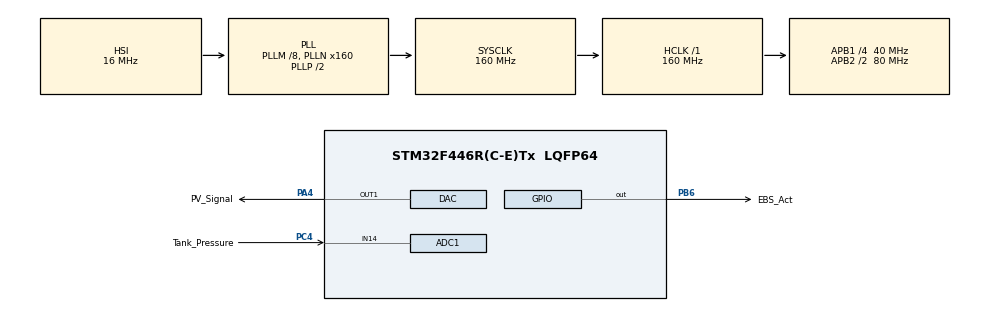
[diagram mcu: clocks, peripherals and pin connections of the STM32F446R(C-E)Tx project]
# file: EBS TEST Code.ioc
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ADC1.Channel-0\#ChannelRegularConversion=ADC_CHANNEL_14
ADC1.ContinuousConvMode=ENABLE
ADC1.DMAContinuousRequests=ENABLE
ADC1.NbrOfConversion=1
ADC1.NbrOfConversionFlag=1
ADC1.Rank-0\#ChannelRegularConversion=1
ADC1.SamplingTime-0\#ChannelRegularConversion=ADC_SAMPLETIME_84CYCLES
ADC1.master=1
DAC.DAC_OutputBuffer=DAC_OUTPUTBUFFER_ENABLE
Dma.ADC1.0.Direction=DMA_PERIPH_TO_MEMORY
Dma.ADC1.0.FIFOMode=DMA_FIFOMODE_DISABLE
Dma.ADC1.0.Instance=DMA2_Stream0
Dma.ADC1.0.MemDataAlignment=DMA_MDATAALIGN_HALFWORD
Dma.ADC1.0.MemInc=DMA_MINC_ENABLE
Dma.ADC1.0.Mode=DMA_CIRCULAR
Dma.ADC1.0.PeriphDataAlignment=DMA_PDATAALIGN_HALFWORD
Dma.ADC1.0.PeriphInc=DMA_PINC_DISABLE
Dma.ADC1.0.Priority=DMA_PRIORITY_LOW
Dma.Request0=ADC1
Mcu.Family=STM32F4
Mcu.Name=STM32F446R(C-E)Tx
Mcu.Package=LQFP64
NVIC.DMA2_Stream0_IRQn=true\:0\:0\:false\:false\:true\:false\:true\:true
NVIC.PriorityGroup=NVIC_PRIORITYGROUP_4
NVIC.TIM6_DAC_IRQn=true\:0\:0\:false\:false\:true\:true\:true\:true
PA13.Mode=Trace_Asynchronous_SW
PA13.Signal=SYS_JTMS-SWDIO
PA14.Mode=Trace_Asynchronous_SW
PA14.Signal=SYS_JTCK-SWCLK
PA4.GPIO_Label=PV_Signal
PA4.Signal=COMP_DAC1_group
PB3.Mode=Trace_Asynchronous_SW
PB3.Signal=SYS_JTDO-SWO
PB6.GPIO_Label=EBS_Act
PB6.Signal=GPIO_Output
PC4.GPIO_Label=Tank_Pressure
PC4.Signal=ADCx_IN14
PH0-OSC_IN.Mode=HSE-External-Oscillator
PH0-OSC_IN.Signal=RCC_OSC_IN
PH1-OSC_OUT.Mode=HSE-External-Oscillator
PH1-OSC_OUT.Signal=RCC_OSC_OUT
ProjectManager.HeapSize=0x200
ProjectManager.StackSize=0x400
ProjectManager.TargetToolchain=STM32CubeIDE
RCC.AHBFreq_Value=160000000
RCC.APB1CLKDivider=RCC_HCLK_DIV4
RCC.APB1Freq_Value=40000000
RCC.APB1TimFreq_Value=80000000
RCC.APB2CLKDivider=RCC_HCLK_DIV2
RCC.APB2Freq_Value=80000000
RCC.APB2TimFreq_Value=160000000
RCC.CortexFreq_Value=160000000
RCC.HCLKFreq_Value=160000000
RCC.PLLM=8
RCC.PLLN=160
RCC.SYSCLKFreq_VALUE=160000000
RCC.SYSCLKSource=RCC_SYSCLKSOURCE_PLLCLK
RCC.USBFreq_Value=160000000
RCC.VCOOutputFreq_Value=320000000
SH.ADCx_IN14.0=ADC1_IN14,IN14
SH.COMP_DAC1_group.0=DAC_OUT1,DAC_OUT1
TIM6.Period=99
TIM6.Prescaler=7999
VP_TIM6_VS_ClockSourceINT.Mode=Enable_Timer
board=custom

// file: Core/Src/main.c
/* USER CODE BEGIN Header */
/**
  ******************************************************************************
  * @file           : main.c
  * @brief          : Main program body
  ******************************************************************************
  * @attention
  *
  * Copyright (c) 2026 STMicroelectronics.
  * All rights reserved.
  *
  * This software is licensed under terms that can be found in the LICENSE file
  * in the root directory of this software component.
  * If no LICENSE file comes with this software, it is provided AS-IS.
  *
  ******************************************************************************
  */
/* USER CODE END Header */
#include "main.h"

/* USER CODE BEGIN Includes */
#include <stdbool.h>
/* USER CODE END Includes */

ADC_HandleTypeDef hadc1;
DMA_HandleTypeDef hdma_adc1;

DAC_HandleTypeDef hdac;

TIM_HandleTypeDef htim6;

/* USER CODE BEGIN PV */
volatile uint16_t adc_raw = 0, value,adc_mV = 0;
volatile uint32_t samples=0;
volatile uint8_t a=1, NO_Valve=0, prev_case=0xFF ;
volatile bool pv_pin_gpio_low=false;
/* USER CODE END PV */

void SystemClock_Config(void);
static void MX_GPIO_Init(void);
static void MX_DMA_Init(void);
static void MX_ADC1_Init(void);
static void MX_TIM6_Init(void);
static void MX_DAC_Init(void);
/* USER CODE BEGIN PFP */
static void reset_all(void);
static void PV_Force_GpioLow(void);
static void PV_Output_Update(uint16_t cmd);
/* USER CODE END PFP */

int main(void)
{

  /* MCU Configuration--------------------------------------------------------*/

  /* Reset of all peripherals, Initializes the Flash interface and the Systick. */
  HAL_Init();

  /* Configure the system clock */
  SystemClock_Config();

  /* Initialize all configured peripherals */
  MX_GPIO_Init();
  MX_DMA_Init();
  MX_ADC1_Init();
  MX_TIM6_Init();
  MX_DAC_Init();
  /* USER CODE BEGIN 2 */
  if (HAL_DAC_Start(&hdac, DAC_CHANNEL_1) != HAL_OK) {
	  Error_Handler();
  }

  if (HAL_ADC_Start_DMA(&hadc1, (uint32_t*)&adc_raw, 1) != HAL_OK) {
	  Error_Handler();
  }

  if (HAL_TIM_Base_Start_IT(&htim6) != HAL_OK) {
	  Error_Handler();
  }
  /* USER CODE END 2 */

  /* Infinite loop */
  /* USER CODE BEGIN WHILE */
  while (1){
	  if(a!=prev_case){
		  reset_all();
		  prev_case=a;
		  }

    switch(a){
      case 1: // you are able to set the value to see how can work the proportional valve and even to tune an find the right thresholds
    	  PV_Output_Update(value);
    	  break;
      case 2: // you should see the proportional valve fully energized and the NO valve de-energize
    	  HAL_GPIO_WritePin(EBS_Act_GPIO_Port, EBS_Act_Pin, GPIO_PIN_RESET);
    	  NO_Valve=1; // 0:energize 1:de-energize
          break;
      case 3: // this make PoC that even if have Proportional Valve set in whatever stage, as long as NO pressure override we are going to see this pressure
    	  HAL_GPIO_WritePin(EBS_Act_GPIO_Port, EBS_Act_Pin, GPIO_PIN_RESET);
    	  NO_Valve=1; // 0:energize 1:de-energize
    	  PV_Output_Update(value);
    	  break;
      default:
    	  break;
    }
    /* USER CODE END WHILE */

  }
}

void SystemClock_Config(void)
{
  RCC_OscInitTypeDef RCC_OscInitStruct = {0};
  RCC_ClkInitTypeDef RCC_ClkInitStruct = {0};

  /** Configure the main internal regulator output voltage
  */
  __HAL_RCC_PWR_CLK_ENABLE();
  __HAL_PWR_VOLTAGESCALING_CONFIG(PWR_REGULATOR_VOLTAGE_SCALE1);

  /** Initializes the RCC Oscillators according to the specified parameters
  * in the RCC_OscInitTypeDef structure.
  */
  RCC_OscInitStruct.OscillatorType = RCC_OSCILLATORTYPE_HSI;
  RCC_OscInitStruct.HSIState = RCC_HSI_ON;
  RCC_OscInitStruct.HSICalibrationValue = RCC_HSICALIBRATION_DEFAULT;
  RCC_OscInitStruct.PLL.PLLState = RCC_PLL_ON;
  RCC_OscInitStruct.PLL.PLLSource = RCC_PLLSOURCE_HSI;
  RCC_OscInitStruct.PLL.PLLM = 8;
  RCC_OscInitStruct.PLL.PLLN = 160;
  RCC_OscInitStruct.PLL.PLLP = RCC_PLLP_DIV2;
  RCC_OscInitStruct.PLL.PLLQ = 2;
  RCC_OscInitStruct.PLL.PLLR = 2;
  if (HAL_RCC_OscConfig(&RCC_OscInitStruct) != HAL_OK)
  {
    Error_Handler();
  }

  /** Initializes the CPU, AHB and APB buses clocks
  */
  RCC_ClkInitStruct.ClockType = RCC_CLOCKTYPE_HCLK|RCC_CLOCKTYPE_SYSCLK
                              |RCC_CLOCKTYPE_PCLK1|RCC_CLOCKTYPE_PCLK2;
  RCC_ClkInitStruct.SYSCLKSource = RCC_SYSCLKSOURCE_PLLCLK;
  RCC_ClkInitStruct.AHBCLKDivider = RCC_SYSCLK_DIV1;
  RCC_ClkInitStruct.APB1CLKDivider = RCC_HCLK_DIV4;
  RCC_ClkInitStruct.APB2CLKDivider = RCC_HCLK_DIV2;

  if (HAL_RCC_ClockConfig(&RCC_ClkInitStruct, FLASH_LATENCY_5) != HAL_OK)
  {
    Error_Handler();
  }
}

static void MX_ADC1_Init(void)
{

  ADC_ChannelConfTypeDef sConfig = {0};

  /** Configure the global features of the ADC (Clock, Resolution, Data Alignment and number of conversion)
  */
  hadc1.Instance = ADC1;
  hadc1.Init.ClockPrescaler = ADC_CLOCK_SYNC_PCLK_DIV4;
  hadc1.Init.Resolution = ADC_RESOLUTION_12B;
  hadc1.Init.ScanConvMode = DISABLE;
  hadc1.Init.ContinuousConvMode = ENABLE;
  hadc1.Init.DiscontinuousConvMode = DISABLE;
  hadc1.Init.ExternalTrigConvEdge = ADC_EXTERNALTRIGCONVEDGE_NONE;
  hadc1.Init.ExternalTrigConv = ADC_SOFTWARE_START;
  hadc1.Init.DataAlign = ADC_DATAALIGN_RIGHT;
  hadc1.Init.NbrOfConversion = 1;
  hadc1.Init.DMAContinuousRequests = ENABLE;
  hadc1.Init.EOCSelection = ADC_EOC_SINGLE_CONV;
  if (HAL_ADC_Init(&hadc1) != HAL_OK)
  {
    Error_Handler();
  }

  /** Configure for the selected ADC regular channel its corresponding rank in the sequencer and its sample time.
  */
  sConfig.Channel = ADC_CHANNEL_14;
  sConfig.Rank = 1;
  sConfig.SamplingTime = ADC_SAMPLETIME_84CYCLES;
  if (HAL_ADC_ConfigChannel(&hadc1, &sConfig) != HAL_OK)
  {
    Error_Handler();
  }

}

static void MX_DAC_Init(void)
{

  DAC_ChannelConfTypeDef sConfig = {0};

  /** DAC Initialization
  */
  hdac.Instance = DAC;
  if (HAL_DAC_Init(&hdac) != HAL_OK)
  {
    Error_Handler();
  }

  /** DAC channel OUT1 config
  */
  sConfig.DAC_Trigger = DAC_TRIGGER_NONE;
  sConfig.DAC_OutputBuffer = DAC_OUTPUTBUFFER_ENABLE;
  if (HAL_DAC_ConfigChannel(&hdac, &sConfig, DAC_CHANNEL_1) != HAL_OK)
  {
    Error_Handler();
  }

}

static void MX_TIM6_Init(void)
{

  TIM_MasterConfigTypeDef sMasterConfig = {0};

  htim6.Instance = TIM6;
  htim6.Init.Prescaler = 7999;
  htim6.Init.CounterMode = TIM_COUNTERMODE_UP;
  htim6.Init.Period = 99;
  htim6.Init.AutoReloadPreload = TIM_AUTORELOAD_PRELOAD_DISABLE;
  if (HAL_TIM_Base_Init(&htim6) != HAL_OK)
  {
    Error_Handler();
  }
  sMasterConfig.MasterOutputTrigger = TIM_TRGO_RESET;
  sMasterConfig.MasterSlaveMode = TIM_MASTERSLAVEMODE_DISABLE;
  if (HAL_TIMEx_MasterConfigSynchronization(&htim6, &sMasterConfig) != HAL_OK)
  {
    Error_Handler();
  }

}

static void MX_DMA_Init(void)
{

  /* DMA controller clock enable */
  __HAL_RCC_DMA2_CLK_ENABLE();

  /* DMA interrupt init */
  /* DMA2_Stream0_IRQn interrupt configuration */
  HAL_NVIC_SetPriority(DMA2_Stream0_IRQn, 0, 0);
  HAL_NVIC_EnableIRQ(DMA2_Stream0_IRQn);

}

static void MX_GPIO_Init(void)
{
  GPIO_InitTypeDef GPIO_InitStruct = {0};

  /* GPIO Ports Clock Enable */
  __HAL_RCC_GPIOH_CLK_ENABLE();
  __HAL_RCC_GPIOA_CLK_ENABLE();
  __HAL_RCC_GPIOC_CLK_ENABLE();
  __HAL_RCC_GPIOB_CLK_ENABLE();

  /*Configure GPIO pin Output Level */
  HAL_GPIO_WritePin(EBS_Act_GPIO_Port, EBS_Act_Pin, GPIO_PIN_RESET);

  /*Configure GPIO pin : EBS_Act_Pin */
  GPIO_InitStruct.Pin = EBS_Act_Pin;
  GPIO_InitStruct.Mode = GPIO_MODE_OUTPUT_PP;
  GPIO_InitStruct.Pull = GPIO_NOPULL;
  GPIO_InitStruct.Speed = GPIO_SPEED_FREQ_LOW;
  HAL_GPIO_Init(EBS_Act_GPIO_Port, &GPIO_InitStruct);

}

/* USER CODE BEGIN 4 */
static void reset_all(void){
	NO_Valve=0;
	value=0; // set value variable for pv to 0
	samples=0; // set tim6 samples to zero
	PV_Force_GpioLow(); // set pv_signal pin to gpio_low
	HAL_GPIO_WritePin(EBS_Act_GPIO_Port, EBS_Act_Pin, GPIO_PIN_SET); //energize valve
}

static void PV_Force_GpioLow(void){
	GPIO_InitTypeDef GPIO_InitStruct = {0};

	if (!pv_pin_gpio_low){
		HAL_DAC_Stop(&hdac, DAC_CHANNEL_1);
		GPIO_InitStruct.Pin = PV_Signal_Pin;
		GPIO_InitStruct.Mode = GPIO_MODE_OUTPUT_PP;
		GPIO_InitStruct.Pull = GPIO_NOPULL;
		GPIO_InitStruct.Speed = GPIO_SPEED_FREQ_LOW;
		HAL_GPIO_Init(PV_Signal_GPIO_Port, &GPIO_InitStruct);
		pv_pin_gpio_low = true;
	}

	HAL_GPIO_WritePin(PV_Signal_GPIO_Port, PV_Signal_Pin, GPIO_PIN_RESET);
}

static void PV_Output_Update(uint16_t cmd){
	GPIO_InitTypeDef GPIO_InitStruct = {0};

	if (cmd == 0U){
		PV_Force_GpioLow();
		return;
	}

	if (pv_pin_gpio_low){
		GPIO_InitStruct.Pin = PV_Signal_Pin;
		GPIO_InitStruct.Mode = GPIO_MODE_ANALOG;
		GPIO_InitStruct.Pull = GPIO_NOPULL;
		HAL_GPIO_Init(PV_Signal_GPIO_Port, &GPIO_InitStruct);
		if (HAL_DAC_Start(&hdac, DAC_CHANNEL_1) != HAL_OK){
			Error_Handler();
		}
		pv_pin_gpio_low = false;
	}

	HAL_DAC_SetValue(&hdac, DAC_CHANNEL_1, DAC_ALIGN_12B_R, cmd);
}
void HAL_TIM_PeriodElapsedCallback(TIM_HandleTypeDef *htim)
{
	if (htim->Instance == TIM6){
		adc_mV = (3300 * adc_raw) / 4095;
		}
}
/* USER CODE END 4 */

void Error_Handler(void)
{
  __disable_irq();
  while (1)
  {
  }
}
